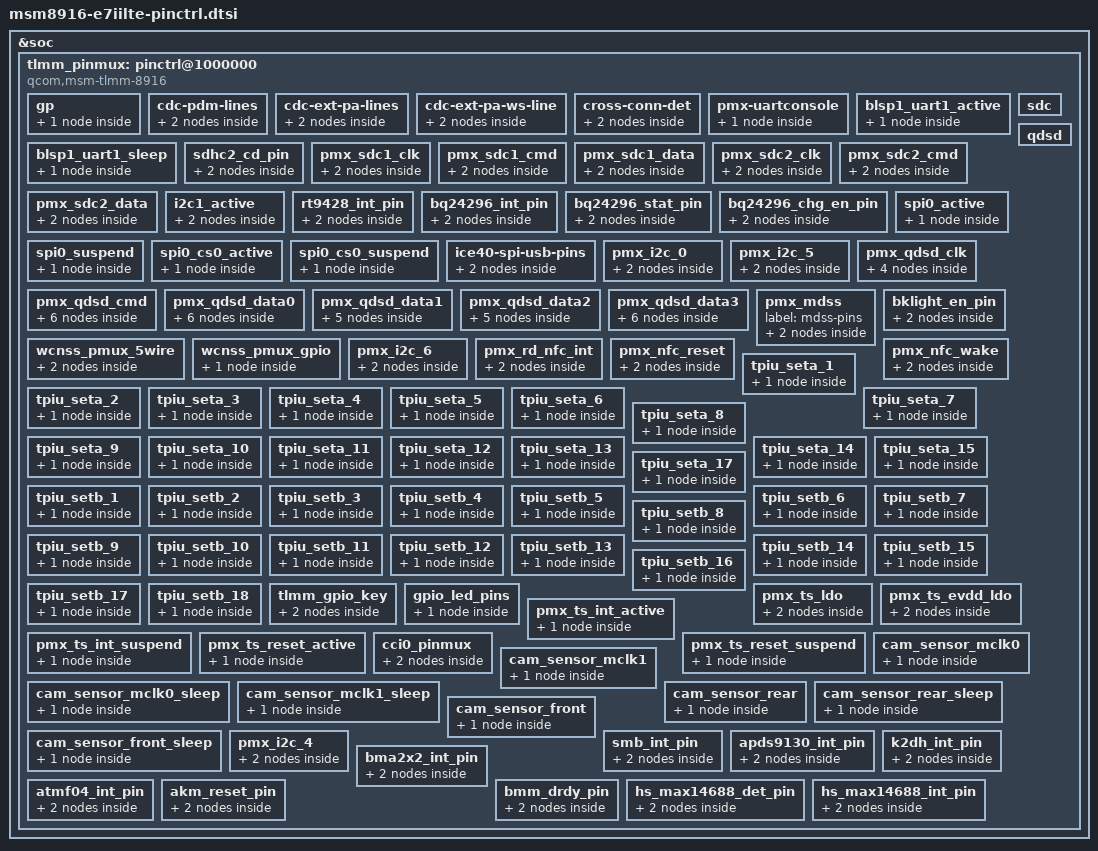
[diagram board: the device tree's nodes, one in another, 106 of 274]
/* Copyright (c) 2013-2014, The Linux Foundation. All rights reserved.
 *
 * This program is free software; you can redistribute it and/or modify
 * it under the terms of the GNU General Public License version 2 and
 * only version 2 as published by the Free Software Foundation.
 *
 * This program is distributed in the hope that it will be useful,
 * but WITHOUT ANY WARRANTY; without even the implied warranty of
 * MERCHANTABILITY or FITNESS FOR A PARTICULAR PURPOSE.  See the
 * GNU General Public License for more details.
 */

&soc {
	tlmm_pinmux: pinctrl@1000000 {
		compatible = "qcom,msm-tlmm-8916";
		reg = <0x1000000 0x300000>;
		interrupts = <0 208 0>;

		/*General purpose pins*/
		gp: gp {
			qcom,pin-type-gp;
			qcom,num-pins = <122>;
			#qcom,pin-cells = <1>;
			msm_gpio: msm_gpio {
				compatible = "qcom,msm-tlmm-gp";
				gpio-controller;
				#gpio-cells = <2>;
				interrupt-controller;
				#interrupt-cells = <2>;
				num_irqs = <122>;
			};
		};
		cdc-pdm-lines {
			qcom,pins = <&gp 63>, <&gp 64>, <&gp 65>,
					<&gp 66>, <&gp 67>, <&gp 68>;
			qcom,num-grp-pins = <6>;
			qcom,pin-func = <1>;
			label = "cdc-pdm-lines";
			cdc_pdm_lines_act: pdm_lines_on {
				drive-strength = <8>;
				bias-pull-none;
			};
			cdc_pdm_lines_sus: pdm_lines_off {
				drive-strength = <2>;
				bias-disable;
			};
		};

		cdc-ext-pa-lines {
			qcom,pins = <&gp 113>, <&gp 114>,
					<&gp 115>, <&gp 116>;
			qcom,num-grp-pins = <4>;
			qcom,pin-func = <1>;
			label = "cdc-ext-pa-lines";
			cdc_ext_pa_act: ext_pa_on {
				drive-strength = <8>;
				bias-pull-none;
			};
			cdc_ext_pa_sus: ext_pa_off {
				drive-strength = <2>;
				bias-disable;
			};
		};

		cdc-ext-pa-ws-line {
			qcom,pins = <&gp 110>;
			qcom,num-grp-pins = <1>;
			qcom,pin-func = <2>;
			label = "cdc-ext-pa-ws-line";
			cdc_ext_pa_ws_act: ext_pa_on {
				drive-strength = <8>;
				bias-pull-none;
			};
			cdc_ext_pa_ws_sus: ext_pa_off {
				drive-strength = <2>;
				bias-disable;
			};
		};

		cross-conn-det {
			qcom,pins = <&gp 120>;
			qcom,num-grp-pins = <1>;
			qcom,pin-func = <0>;
			label = "cross-conn-det-sw";
			cross_conn_det_act: lines_on {
				drive-strength = <8>;
				bias-pull-none;
			};
			cross_conn_det_sus: lines_off {
				drive-strength = <2>;
				bias-disable;
			};
		};
		pmx-uartconsole {
			qcom,pins = <&gp 4>, <&gp 5>;
			qcom,num-grp-pins = <2>;
			qcom,pin-func = <2>;
			label = "uart-console";

		uart_console_sleep: uart-console {
				drive-strength = <2>;
				bias-pull-down;
			};
		};

		blsp1_uart1_active {
			qcom,pins = <&gp 0>, <&gp 1>, <&gp 2>, <&gp 3>;
			qcom,num-grp-pins = <4>;
			qcom,pin-func = <2>;
		        label = "blsp1_uart1_active";

			hsuart_active: default {
				drive-strength = <16>;
				bias-disable;
			};
		};

		blsp1_uart1_sleep {
			qcom,pins = <&gp 0>, <&gp 1>, <&gp 2>, <&gp 3>;
			qcom,num-grp-pins = <4>;
			qcom,pin-func = <0>;
		        label = "blsp1_uart1_sleep";

			hsuart_sleep: sleep {
				drive-strength = <2>;
				bias-disable;
			};
		};

		sdhc2_cd_pin {
			qcom,pins = <&gp 38>;
			qcom,num-grp-pins = <1>;
			qcom,pin-func = <0>;
			label = "cd-gpio";
			sdc2_cd_on: cd_on {
				drive-strength = <2>;
				bias-pull-up;
			};
			sdc2_cd_off: cd_off {
				drive-strength = <2>;
				bias-disable;
			};
		};

		/* SDC pin type */
		sdc: sdc {
			qcom,pin-type-sdc;
			/* 0-2 for sdc1 4-6 for sdc2 */
			qcom,num-pins = <7>;
			/* Order of pins */
			/* SDC1: CLK -> 0, CMD -> 1, DATA -> 2 */
			/* SDC2: CLK -> 4, CMD -> 5, DATA -> 6 */
			#qcom,pin-cells = <1>;
		};

		pmx_sdc1_clk {
			qcom,pins = <&sdc 0>;
			qcom,num-grp-pins = <1>;
			label = "sdc1-clk";
			sdc1_clk_on: clk_on {
				bias-disable; /* NO pull */
				drive-strength = <14>; /* 14 MA */
			};
			sdc1_clk_off: clk_off {
				bias-disable; /* NO pull */
				drive-strength = <2>; /* 2 MA */
			};
		};

		pmx_sdc1_cmd {
			qcom,pins = <&sdc 1>;
			qcom,num-grp-pins = <1>;
			label = "sdc1-cmd";
			sdc1_cmd_on: cmd_on {
				bias-pull-up; /* pull up */
				drive-strength = <8>; /* 8 MA */
			};
			sdc1_cmd_off: cmd_off {
				bias-pull-up; /* pull up */
				drive-strength = <2>; /* 2 MA */
			};
		};

		pmx_sdc1_data {
			qcom,pins = <&sdc 2>;
			qcom,num-grp-pins = <1>;
			label = "sdc1-data";
			sdc1_data_on: data_on {
				bias-pull-up; /* pull up */
				drive-strength = <8>; /* 8 MA */
			};
			sdc1_data_off: data_off {
				bias-pull-up; /* pull up */
				drive-strength = <2>; /* 2 MA */
			};
		};

		pmx_sdc2_clk {
			qcom,pins = <&sdc 4>;
			qcom,num-grp-pins = <1>;
			label = "sdc2-clk";
			sdc2_clk_on: clk_on {
				bias-disable; /* NO pull */
				drive-strength = <16>; /* 16 MA */
			};
			sdc2_clk_off: clk_off {
				bias-disable; /* NO pull */
				drive-strength = <2>; /* 2 MA */
			};
		};

		pmx_sdc2_cmd {
			qcom,pins = <&sdc 5>;
			qcom,num-grp-pins = <1>;
			label = "sdc2-cmd";
			sdc2_cmd_on: cmd_on {
				bias-pull-up; /* pull up */
				drive-strength = <10>; /* 10 MA */
			};
			sdc2_cmd_off: cmd_off {
				bias-pull-up; /* pull up */
				drive-strength = <2>; /* 2 MA */
			};
		};

		pmx_sdc2_data {
			qcom,pins = <&sdc 6>;
			qcom,num-grp-pins = <1>;
			label = "sdc2-data";
			sdc2_data_on: data_on {
				bias-pull-up; /* pull up */
				drive-strength = <10>; /* 10 MA */
			};
			sdc2_data_off: data_off {
				bias-pull-up; /* pull up */
				drive-strength = <2>; /* 2 MA */
			};
		};

		/* BQ24296 Charger & RT9428 FuelGauge I2C */
		i2c1_active {
			/* CLK, DATA */
			qcom,pins = <&gp 2>, <&gp 3>;
			qcom,num-grp-pins = <2>;
			qcom,pin-func = <3>;
			label = "i2c1";
			/* active state */
			i2c_1_active: active {
				  drive-strength = <8>; /* 8 MA */
				  bias-disable = <0>; /* No PULL */
			  };
			i2c_1_sleep: sleep {
				 drive-strength = <8>; /* 8 MA */
				 bias-disable = <0>; /* No PULL */
			 };
		};

                /* RT9428 INT pin conifg */
		rt9428_int_pin {
			qcom,pins = <&gp 1>;
			qcom,num-grp-pins = <1>;
			qcom,pin-func = <0>;
			label = "rt9428_int_gpio";
			rt9428_int_active: rt9428_int_active {
				drive-strength = <6>;   /* 6 MA */
				bias-pull-up;           /* PULL UP*/
			};
			rt9428_int_sleep: rt9428_int_sleep {
				drive-strength = <6>;   /* 6 MA */
				bias-pull-up;           /* PULL UP */
			};

		};

		/* BQ24296 INT pin conifg */
		bq24296_int_pin {
			qcom,pins = <&gp 54>;
			qcom,num-grp-pins = <1>;
			qcom,pin-func = <0>;
			label = "bq24296_int_gpio";
			bq24296_int_active: bq24296_int_active {
				drive-strength = <6>;   /* 6 MA */
				bias-pull-up;           /* PULL UP*/
			};
			bq24296_int_sleep: bq24296_int_sleep {
				drive-strength = <6>;   /* 6 MA */
				bias-pull-up;           /* PULL UP */
			};
		};

		/* BQ24296 STAT pin config */
		bq24296_stat_pin {
			qcom,pins = <&gp 114>;
			qcom,num-grp-pins = <1>;
			qcom,pin-func = <0>;
			label = "bq24296_stat_gpio";
			bq24296_stat_active: bq24296_stat_active {
				drive-strength = <6>;   /* 6 MA */
				bias-pull-up;           /* PULL UP*/
			};
			bq24296_stat_sleep: bq24296_stat_sleep {
				drive-strength = <6>;   /* 6 MA */
				bias-pull-up;           /* PULL UP */
			};
		};

		/* BQ24296 CE pin config */
		bq24296_chg_en_pin {
			qcom,pins = <&gp 17>;
			qcom,num-grp-pins = <1>;
			qcom,pin-func = <0>;
			label = "bq24296_chg_en_gpio";
			bq24296_chg_en_active: bq24296_chg_en_active {
				drive-strength = <6>;   /* 6 MA */
				bias-pull-down = <0>;   /* PULL DOWN*/
			};
			bq24296_chg_en_sleep: bq24296_chg_en_sleep {
				drive-strength = <6>;   /* 6 MA */
				bias-pull-down = <0>;   /* PULL DOWN */
			};
		};

		spi0_active {
			/* MOSI, MISO, CLK */
			qcom,pins = <&gp 8>, <&gp 9>, <&gp 11>;
			qcom,num-grp-pins = <3>;
			qcom,pin-func = <1>;
			label = "spi0-active";
			/* active state */
			spi0_default: default {
				drive-strength = <12>; /* 12 MA */
				bias-disable = <0>; /* No PULL */
			};
		};

		spi0_suspend {
			/* MOSI, MISO, CLK */
			qcom,pins = <&gp 8>, <&gp 9>, <&gp 11>;
			qcom,num-grp-pins = <3>;
			qcom,pin-func = <0>;
			label = "spi0-suspend";
			/* suspended state */
			spi0_sleep: sleep {
				drive-strength = <2>; /* 2 MA */
				bias-pull-down; /* pull down */
			};
		};
		spi0_cs0_active {
			/* CS */
			qcom,pins = <&gp 10>;
			qcom,num-grp-pins = <1>;
			qcom,pin-func = <1>;
			label = "spi0-cs0-active";
			spi0_cs0_active: cs0_active {
				drive-strength = <2>;
				bias-disable = <0>;
			};
		};


		spi0_cs0_suspend {
			/* CS */
			qcom,pins = <&gp 10>;
			qcom,num-grp-pins = <1>;
			qcom,pin-func = <0>;
			label = "spi0-cs0-suspend";
			spi0_cs0_sleep: cs0_sleep {
				drive-strength = <2>;
				bias-disable = <0>;
			};
		};

		ice40-spi-usb-pins {
			qcom,pins = <&gp 0>, <&gp 1>, <&gp 3>, <&gp 114>;
			qcom,num-grp-pins = <4>;
			qcom,pin-func = <0>;
			label = "ice40-spi-usb-pins";

			/* active state */
			ice40_default: default {
				drive-strength = <8>;
				bias-disable;
			};

			/* sleep state */
			ice40_sleep: sleep {
				drive-strength = <2>;
				bias-pull-down;
			};
		};

		pmx_i2c_0 {
			/* CLK, DATA */
			qcom,pins = <&gp 7>, <&gp 6>;
			qcom,num-grp-pins = <2>;
			qcom,pin-func = <3>;
			label = "pmx_i2c_0";

			i2c_0_active: i2c_0_active {
				drive-strength = <2>; /* 2 MA */
				bias-disable;         /* No PULL */
			};

			i2c_0_sleep: i2c_0_sleep {
				drive-strength = <2>; /* 2 MA */
				bias-disable;	      /* No PULL */
			};
		};

		pmx_i2c_5 {
			/* CLK, DATA */
			qcom,pins = <&gp 19>, <&gp 18>;
			qcom,num-grp-pins = <2>;
			qcom,pin-func = <2>;
			label = "pmx_i2c_5";

			i2c_5_active: i2c_5_active {
				drive-strength = <2>; /* 2 MA */
				bias-disable = <0>; /* No PULL */
			};

			i2c_5_sleep: i2c_5_sleep {
				drive-strength = <2>; /* 2 MA */
				bias-disable = <0>; /* No PULL */
			};
		};

		/* QDSD pin type */
		qdsd: qdsd {
			qcom,pin-type-qdsd;
			/* 0-> clk, 1 -> cmd, 2->data0, 3->data1, 4->data2, 5->data3 */
			qcom,num-pins = <6>;

			#qcom,pin-cells = <1>;
		};

		pmx_qdsd_clk {
			qcom,pins = <&qdsd 0>;
			qcom,num-grp-pins = <1>;
			label = "qdsd-clk";
			qdsd_clk_sdcard: clk_sdcard {
				bias-disable; /* NO pull */
				drive-strength = <7>; /* 7 MA */
			};
			qdsd_clk_trace: clk_trace {
				bias-pull-down; /* pull down */
				drive-strength = <0>; /* 0 MA */
			};
			qdsd_clk_swdtrc: clk_swdtrc {
				bias-pull-down; /* pull down */
				drive-strength = <0>; /* 0 MA */
			};
			qdsd_clk_spmi: clk_spmi {
				bias-pull-down; /* pull down */
				drive-strength = <0>; /* 0 MA */
			};
		};

		pmx_qdsd_cmd {
			qcom,pins = <&qdsd 1>;
			qcom,num-grp-pins = <1>;
			label = "qdsd-cmd";
			qdsd_cmd_sdcard: cmd_sdcard {
				bias-pull-down; /* pull down */
				drive-strength = <3>; /* 3 MA */
			};
			qdsd_cmd_trace: cmd_trace {
				bias-pull-down; /* pull down */
				drive-strength = <0>; /* 0 MA */
			};
			qdsd_cmd_swduart: cmd_uart {
				bias-pull-up; /* pull up */
				drive-strength = <0>; /* 0 MA */
			};
			qdsd_cmd_swdtrc: cmd_swdtrc {
				bias-pull-up; /* pull up */
				drive-strength = <0>; /* 0 MA */
			};
			qdsd_cmd_jtag: cmd_jtag {
				bias-disable; /* NO pull */
				drive-strength = <3>; /* 3 MA */
			};
			qdsd_cmd_spmi: cmd_spmi {
				bias-pull-down; /* pull down */
				drive-strength = <4>; /* 4 MA */
			};
		};

		pmx_qdsd_data0 {
			qcom,pins = <&qdsd 2>;
			qcom,num-grp-pins = <1>;
			label = "qdsd-data0";
			qdsd_data0_sdcard: data0_sdcard {
				bias-pull-down; /* pull down */
				drive-strength = <3>; /* 3 MA */
			};
			qdsd_data0_trace: data0_trace {
				bias-pull-down; /* pull down */
				drive-strength = <0>; /* 0 MA */
			};
			qdsd_data0_swduart: data0_uart {
				bias-pull-down; /* pull down */
				drive-strength = <0>; /* 0 MA */
			};
			qdsd_data0_swdtrc: data0_swdtrc {
				bias-pull-down; /* pull down */
				drive-strength = <0>; /* 0 MA */
			};
			qdsd_data0_jtag: data0_jtag {
				bias-pull-up; /* pull up */
				drive-strength = <0>; /* 0 MA */
			};
			qdsd_data0_spmi: data0_spmi {
				bias-pull-down; /* pull down */
				drive-strength = <0>; /* 0 MA */
			};
		};

		pmx_qdsd_data1 {
			qcom,pins = <&qdsd 3>;
			qcom,num-grp-pins = <1>;
			label = "qdsd-data1";
			qdsd_data1_sdcard: data1_sdcard {
				bias-pull-down; /* pull down */
				drive-strength = <3>; /* 3 MA */
			};
			qdsd_data1_trace: data1_trace {
				bias-pull-down; /* pull down */
				drive-strength = <0>; /* 0 MA */
			};
			qdsd_data1_swduart: data1_uart {
				bias-pull-down; /* pull down */
				drive-strength = <0>; /* 0 MA */
			};
			qdsd_data1_swdtrc: data1_swdtrc {
				bias-pull-down; /* pull down */
				drive-strength = <0>; /* 0 MA */
			};
			qdsd_data1_jtag: data1_jtag {
				bias-pull-down; /* pull down */
				drive-strength = <0>; /* 0 MA */
			};
		};

		pmx_qdsd_data2 {
			qcom,pins = <&qdsd 4>;
			qcom,num-grp-pins = <1>;
			label = "qdsd-data2";
			qdsd_data2_sdcard: data2_sdcard {
				bias-pull-down; /* pull down */
				drive-strength = <3>; /* 3 MA */
			};
			qdsd_data2_trace: data2_trace {
				bias-pull-down; /* pull down */
				drive-strength = <0>; /* 0 MA */
			};
			qdsd_data2_swduart: data2_uart {
				bias-pull-down; /* pull down */
				drive-strength = <0>; /* 0 MA */
			};
			qdsd_data2_swdtrc: data2_swdtrc {
				bias-pull-down; /* pull down */
				drive-strength = <0>; /* 0 MA */
			};
			qdsd_data2_jtag: data2_jtag {
				bias-pull-up; /* pull up */
				drive-strength = <3>; /* 3 MA */
			};
		};

		pmx_qdsd_data3 {
			qcom,pins = <&qdsd 5>;
			qcom,num-grp-pins = <1>;
			label = "qdsd-data3";
			qdsd_data3_sdcard: data3_sdcard {
				bias-pull-down; /* pull down */
				drive-strength = <3>; /* 3 MA */
			};
			qdsd_data3_trace: data3_trace {
				bias-pull-down; /* pull down */
				drive-strength = <0>; /* 0 MA */
			};
			qdsd_data3_swduart: data3_uart {
				bias-pull-up; /* pull up */
				drive-strength = <0>; /* 0 MA */
			};
			qdsd_data3_swdtrc: data3_swdtrc {
				bias-pull-up; /* pull up */
				drive-strength = <0>; /* 0 MA */
			};
			qdsd_data3_jtag: data3_jtag {
				bias-pull-up; /* pull up */
				drive-strength = <0>; /* 0 MA */
			};
			qdsd_data3_spmi: data3_spmi {
				bias-pull-down; /* pull down */
				drive-strength = <3>; /* 3 MA */
			};
		};

		pmx_mdss: pmx_mdss {
			label = "mdss-pins";
			mdss_dsi_active: active {
				drive-strength = <8>; /* 8 mA */
				bias-disable = <0>; /* no pull */
			};
			mdss_dsi_suspend: suspend {
				drive-strength = <2>; /* 2 mA */
				bias-disable = <0>; /* pull down */
			};
		};

		/* backlight enable pin config */
		bklight_en_pin {
			qcom,pins = <&gp 98>;
			qcom,num-grp-pins = <1>;
			qcom,pin-func = <0>;
			label = "bklight_en_pin";
			bklight_en_active: bklight_en_active {
				drive-strength = <6>;   /* 6 MA */
				bias-disable; 		/* NO PULL */
			};
			bklight_en_suspend: bklight_en_suspend {
				drive-strength = <6>;   /* 6 MA */
				bias-disable; 		/* NO PULL */
			};
		};

		wcnss_pmux_5wire: wcnss_pmux_5wire {
			/* Uses general purpose pins */
			qcom,pins = <&gp 40>, <&gp 41>,
				    <&gp 42>, <&gp 43>,
				    <&gp 44>;
			qcom,num-grp-pins = <5>;
			qcom,pin-func = <1>;
			label = "wcnss_5wire_pins";
			/* Active configuration of bus pins */
			wcnss_default: wcnss_default {
			        drive-strength = <6>; /* 6 MA */
			        bias-pull-up; /* PULL UP */
			};
			wcnss_sleep: wcnss_sleep {
			        drive-strength = <2>; /* 2 MA */
			        bias-pull-down; /* PULL Down */
			};
		};

		wcnss_pmux_gpio: wcnss_pmux_gpio {
			/* Uses general purpose pins */
			qcom,pins = <&gp 40>, <&gp 41>,
				    <&gp 42>, <&gp 43>,
				    <&gp 44>;
			qcom,num-grp-pins = <5>;
			qcom,pin-func = <0>;
			label = "wcnss_5gpio_pins";
			/* Active configuration of bus pins */
			wcnss_gpio_default: wcnss_gpio_default {
			        drive-strength = <6>; /* 6 MA */
			        bias-pull-up; /* PULL UP */
			};
		};

		pmx_i2c_6 {
			/* CLK, DATA */
			qcom,pins = <&gp 22>, <&gp 23>;
			qcom,num-grp-pins = <2>;
			qcom,pin-func = <2>;
			label = "pmx_i2c_6";
			/* active state */
			i2c_6_active: i2c_6_active{
				drive-strength = <2>; /* 2 MA */
				bias-disable; /* No PULL */
			};
			/*suspended state */
			i2c_6_sleep: i2c_6_sleep {
				drive-strength = <2>; /* 2 MA */
				bias-disable; /* No PULL */
			};
		};

		pmx_rd_nfc_int{
			qcom,pins = <&gp 21>;
			qcom,pin-func = <0>;
			qcom,num-grp-pins = <1>;
			label = "pmx_nfc_int";

			nfc_int_active: active {
				drive-strength = <6>;
				bias-pull-up;
			};

			nfc_int_suspend: suspend {
				drive-strength = <6>;
				bias-pull-up;
			};
		};

		pmx_nfc_reset{
			qcom,pins = <&gp 20>;
			qcom,pin-func = <0>;
			qcom,num-grp-pins = <1>;
			label = "pmx_nfc_disable";

			nfc_disable_active: active {
				drive-strength = <6>;
				bias-pull-up;
			};

			nfc_disable_suspend: suspend {
				drive-strength = <6>;
				bias-disable;
			};
		};

		pmx_nfc_wake{
			qcom,pins = <&gp 118>;
			qcom,pin-func = <0>;
			qcom,num-grp-pins = <1>;
			label = "pmx_nfc_wake";

			nfc_wake_active: active {
				drive-strength = <6>;
				bias-pull-up;
			};
			nfc_wake_suspend: suspend {
				drive-strength = <6>;
				bias-disable;
			};
		};

		/* CoreSight */
		tpiu_seta_1 {
			qcom,pins = <&gp 8>;
			qcom,num-grp-pins = <1>;
			qcom,pin-func = <3>;
			label = "tpiu-seta-1";
			seta_1: seta {
				drive-strength = <16>;
				bias-disable;
			};
		};

		tpiu_seta_2 {
			qcom,pins = <&gp 9>;
			qcom,num-grp-pins = <1>;
			qcom,pin-func = <2>;
			label = "tpiu-seta-2";
			seta_2: seta {
				drive-strength = <16>;
				bias-disable;
			};
		};

		tpiu_seta_3 {
			qcom,pins = <&gp 10>;
			qcom,num-grp-pins = <1>;
			qcom,pin-func = <3>;
			label = "tpiu-seta-3";
			seta_3: seta {
				drive-strength = <16>;
				bias-disable;
			};
		};

		tpiu_seta_4 {
			qcom,pins = <&gp 39>;
			qcom,num-grp-pins = <1>;
			qcom,pin-func = <2>;
			label = "tpiu-seta-4";
			seta_4: seta {
				drive-strength = <16>;
				bias-disable;
			};
		};

		tpiu_seta_5 {
			qcom,pins = <&gp 40>;
			qcom,num-grp-pins = <1>;
			qcom,pin-func = <2>;
			label = "tpiu-seta-5";
			seta_5: seta {
				drive-strength = <16>;
				bias-disable;
			};
		};

		tpiu_seta_6 {
			qcom,pins = <&gp 41>;
			qcom,num-grp-pins = <1>;
			qcom,pin-func = <2>;
			label = "tpiu-seta-6";
			seta_6: seta {
				drive-strength = <16>;
				bias-disable;
			};
		};

		tpiu_seta_7 {
			qcom,pins = <&gp 42>;
			qcom,num-grp-pins = <1>;
			qcom,pin-func = <2>;
			label = "tpiu-seta-7";
			seta_7: seta {
				drive-strength = <16>;
				bias-disable;
			};
		};

		tpiu_seta_8 {
			qcom,pins = <&gp 43>;
			qcom,num-grp-pins = <1>;
			qcom,pin-func = <3>;
			label = "tpiu-seta-8";
			seta_8: seta {
				drive-strength = <16>;
				bias-disable;
			};
		};

		tpiu_seta_9 {
			qcom,pins = <&gp 45>;
			qcom,num-grp-pins = <1>;
			qcom,pin-func = <3>;
			label = "tpiu-seta-9";
			seta_9: seta {
				drive-strength = <16>;
				bias-disable;
			};
		};

		tpiu_seta_10 {
			qcom,pins = <&gp 46>;
			qcom,num-grp-pins = <1>;
			qcom,pin-func = <2>;
			label = "tpiu-seta-10";
			seta_10: seta {
				drive-strength = <16>;
				bias-disable;
			};
		};

		tpiu_seta_11 {
			qcom,pins = <&gp 47>;
			qcom,num-grp-pins = <1>;
			qcom,pin-func = <3>;
			label = "tpiu-seta-11";
			seta_11: seta {
				drive-strength = <16>;
				bias-disable;
			};
		};

		tpiu_seta_12 {
			qcom,pins = <&gp 48>;
			qcom,num-grp-pins = <1>;
			qcom,pin-func = <2>;
			label = "tpiu-seta-12";
			seta_12: seta {
				drive-strength = <16>;
				bias-disable;
			};
		};

		tpiu_seta_13 {
			qcom,pins = <&gp 62>;
			qcom,num-grp-pins = <1>;
			qcom,pin-func = <2>;
			label = "tpiu-seta-13";
			seta_13: seta {
				drive-strength = <16>;
				bias-disable;
			};
		};

		tpiu_seta_14 {
			qcom,pins = <&gp 69>;
			qcom,num-grp-pins = <1>;
			qcom,pin-func = <2>;
			label = "tpiu-seta-14";
			seta_14: seta {
				drive-strength = <16>;
				bias-disable;
			};
		};

		tpiu_seta_15 {
			qcom,pins = <&gp 112>;
			qcom,num-grp-pins = <1>;
			qcom,pin-func = <5>;
			label = "tpiu-seta-15";
			seta_15: seta {
				drive-strength = <16>;
				bias-disable;
			};
		};

		tpiu_seta_17 {
			qcom,pins = <&gp 114>;
			qcom,num-grp-pins = <1>;
			qcom,pin-func = <8>;
			label = "tpiu-seta-17";
			seta_17: seta {
				drive-strength = <16>;
				bias-disable;
			};
		};

		tpiu_setb_1 {
			qcom,pins = <&gp 4>;
			qcom,num-grp-pins = <1>;
			qcom,pin-func = <5>;
			label = "tpiu-setb-1";
			setb_1: setb {
				drive-strength = <16>;
				bias-disable;
			};
		};

		tpiu_setb_2 {
			qcom,pins = <&gp 5>;
			qcom,num-grp-pins = <1>;
			qcom,pin-func = <5>;
			label = "tpiu-setb-2";
			setb_2: setb {
				drive-strength = <16>;
				bias-disable;
			};
		};

		tpiu_setb_3 {
			qcom,pins = <&gp 26>;
			qcom,num-grp-pins = <1>;
			qcom,pin-func = <7>;
			label = "tpiu-setb-3";
			setb_3: setb {
				drive-strength = <16>;
				bias-disable;
			};
		};

		tpiu_setb_4 {
			qcom,pins = <&gp 27>;
			qcom,num-grp-pins = <1>;
			qcom,pin-func = <9>;
			label = "tpiu-setb-4";
			setb_4: setb {
				drive-strength = <16>;
				bias-disable;
			};
		};

		tpiu_setb_5 {
			qcom,pins = <&gp 28>;
			qcom,num-grp-pins = <1>;
			qcom,pin-func = <7>;
			label = "tpiu-setb-5";
			setb_5: setb {
				drive-strength = <16>;
				bias-disable;
			};
		};

		tpiu_setb_6 {
			qcom,pins = <&gp 29>;
			qcom,num-grp-pins = <1>;
			qcom,pin-func = <7>;
			label = "tpiu-setb-6";
			setb_6: setb {
				drive-strength = <16>;
				bias-disable;
			};
		};

		tpiu_setb_7 {
			qcom,pins = <&gp 30>;
			qcom,num-grp-pins = <1>;
			qcom,pin-func = <9>;
			label = "tpiu-setb-7";
			setb_7: setb {
				drive-strength = <16>;
				bias-disable;
			};
		};

		tpiu_setb_8 {
			qcom,pins = <&gp 31>;
			qcom,num-grp-pins = <1>;
			qcom,pin-func = <10>;
			label = "tpiu-setb-8";
			setb_8: setb {
				drive-strength = <16>;
				bias-disable;
			};
		};

		tpiu_setb_9 {
			qcom,pins = <&gp 32>;
			qcom,num-grp-pins = <1>;
			qcom,pin-func = <10>;
			label = "tpiu-setb-9";
			setb_9: setb {
				drive-strength = <16>;
				bias-disable;
			};
		};

		tpiu_setb_10 {
			qcom,pins = <&gp 33>;
			qcom,num-grp-pins = <1>;
			qcom,pin-func = <9>;
			label = "tpiu-setb-10";
			setb_10: setb {
				drive-strength = <16>;
				bias-disable;
			};
		};

		tpiu_setb_11 {
			qcom,pins = <&gp 34>;
			qcom,num-grp-pins = <1>;
			qcom,pin-func = <9>;
			label = "tpiu-setb-11";
			setb_11: setb {
				drive-strength = <16>;
				bias-disable;
			};
		};

		tpiu_setb_12 {
			qcom,pins = <&gp 35>;
			qcom,num-grp-pins = <1>;
			qcom,pin-func = <9>;
			label = "tpiu-setb-12";
			setb_12: setb {
				drive-strength = <16>;
				bias-disable;
			};
		};

		tpiu_setb_13 {
			qcom,pins = <&gp 36>;
			qcom,num-grp-pins = <1>;
			qcom,pin-func = <8>;
			label = "tpiu-setb-13";
			setb_13: setb {
				drive-strength = <16>;
				bias-disable;
			};
		};

		tpiu_setb_14 {
			qcom,pins = <&gp 37>;
			qcom,num-grp-pins = <1>;
			qcom,pin-func = <7>;
			label = "tpiu-setb-14";
			setb_14: setb {
				drive-strength = <16>;
				bias-disable;
			};
		};

		tpiu_setb_15 {
			qcom,pins = <&gp 110>;
			qcom,num-grp-pins = <1>;
			qcom,pin-func = <4>;
			label = "tpiu-setb-15";
			setb_15: setb {
				drive-strength = <16>;
				bias-disable;
			};
		};

		tpiu_setb_16 {
			qcom,pins = <&gp 111>;
			qcom,num-grp-pins = <1>;
			qcom,pin-func = <1>;
			label = "tpiu-setb-16";
			setb_16: setb {
				drive-strength = <16>;
				bias-disable;
			};
		};

		tpiu_setb_17 {
			qcom,pins = <&gp 120>;
			qcom,num-grp-pins = <1>;
			qcom,pin-func = <10>;
			label = "tpiu-setb-17";
			setb_17: setb {
				drive-strength = <16>;
				bias-disable;
			};
		};

		tpiu_setb_18 {
			qcom,pins = <&gp 121>;
			qcom,num-grp-pins = <1>;
			qcom,pin-func = <11>;
			label = "tpiu-setb-18";
			setb_18: setb {
				drive-strength = <16>;
				bias-disable;
			};
		};

		tlmm_gpio_key {
			qcom,pins = <&gp 107>, <&gp 108>;
			qcom,pin-func = <0>;
			qcom,num-grp-pins = <2>;
			label = "tlmm_gpio_key";
			gpio_key_active: gpio_key_active {
				drive-strength = <2>;
				bias-pull-up;
			};
			gpio_key_suspend: gpio_key_suspend {
				drive-strength = <2>;
				bias-pull-up;
			};
		};

		gpio_led_pins {
			qcom,pins = <&gp 8>, <&gp 9>, <&gp 10>;
			qcom,num-grp-pins = <3>;
			label = "gpio-led-pins";
			gpio_led_off: led_off {
				drive-strength = <2>;
				bias-disable;
				output-low;
			};
		};

		/* add pingrp for touchscreen */
		pmx_ts_ldo {
			qcom,pins = <&gp 32>, <&gp 34>, <&gp 36>;
			qcom,pin-func = <0>;
			qcom,num-grp-pins = <3>;
			label = "pmx_ts_ldo_active";

			ts_ldo_active: ts_ldo_active {
				drive-strength = <2>;
				output-high;
			};

			ts_ldo_suspend: ts_ldo_suspend {
				drive-strength = <2>;
				output-low;
			};
		};

		pmx_ts_evdd_ldo {
			qcom,pins = <&gp 9>;
			qcom,pin-func = <0>;
			qcom,num-grp-pins = <1>;
			label = "pmx_ts_evdd_ldo_active";

			ts_evdd_ldo_active: ts_evdd_ldo_active {
				drive-strength = <2>;
				output-high;
			};

			ts_evdd_ldo_suspend: ts_evdd_ldo_suspend {
				drive-strength = <2>;
				output-low;
			};
		};


		/* add pingrp for touchscreen */
		pmx_ts_int_active {
			qcom,pins = <&gp 13>;
			qcom,pin-func = <0>;
			qcom,num-grp-pins = <1>;
			label = "pmx_ts_int_active";

			ts_int_active: ts_int_active {
				drive-strength = <16>;
				bias-pull-up;
			};
		};

		pmx_ts_int_suspend {
			qcom,pins = <&gp 13>;
			qcom,pin-func = <0>;
			qcom,num-grp-pins = <1>;
			label = "pmx_ts_int_suspend";

			ts_int_suspend: ts_int_suspend {
				drive-strength = <2>;
				bias-pull-down;
			};
		};

		pmx_ts_reset_active {
			qcom,pins = <&gp 12>;
			qcom,pin-func = <0>;
			qcom,num-grp-pins = <1>;
			label = "pmx_ts_reset_active";

			ts_reset_active: ts_reset_active {
				drive-strength = <16>;
				bias-pull-up;
			};
		};

		pmx_ts_reset_suspend {
			qcom,pins = <&gp 12>;
			qcom,pin-func = <0>;
			qcom,num-grp-pins = <1>;
			label = "pmx_ts_reset_suspend";

			ts_reset_suspend: ts_reset_suspend {
				drive-strength = <2>;
				bias-pull-down;
			};
		};

		/*
		pmx_ts_reset {
			qcom,pins = <&gp 12>;
			qcom,pin-func = <0>;
			qcom,num-grp-pins = <1>;
			label = "pmx_ts_reset_active";

			ts_reset_active: ts_reset_active {
				drive-strength = <2>;
				output-high;
			};

			ts_reset_suspend: ts_reset_suspend {
				drive-strength = <2>;
				output-low;
			};
		};

		pmx_ts_int {
			qcom,pins = <&gp 13>;
			qcom,pin-func = <0>;
			qcom,num-grp-pins = <1>;
			label = "pmx_ts_int_active";

			ts_int_active: ts_int_active {
				drive-strength = <2>;
				bias-pull-up;
			};

			ts_int_suspend: ts_int_suspend {
				drive-strength = <2>;
				bias-pull-down;
			};
		};
		*/

		cci0_pinmux {
			/* CLK, DATA */
			qcom,pins = <&gp 29>, <&gp 30>;
			qcom,num-grp-pins = <2>;
			qcom,pin-func = <1>;
			label = "cci0";
			/* active state */
			cci0_default: default {
				drive-strength = <2>; /* 2 MA */
				bias-disable = <0>; /* No PULL */
			};
			/*suspended state */
			cci0_sleep: sleep {
				drive-strength = <2>; /* 2 MA */
				bias-disable = <0>; /* No PULL */
			};
		};

		cam_sensor_mclk0 {
			/* MCLK */
			qcom,pins = <&gp 26>;
			qcom,num-grp-pins = <1>;
			qcom,pin-func = <1>;
			label = "cam-sensor-mclk0";
			/* active state */
			cam_sensor_mclk0_default: default {
				drive-strength = <2>; /* 2 MA */
				bias-disable = <0>; /* No PULL */
			};
		};

		cam_sensor_mclk0_sleep {
			/* MCLK */
			qcom,pins = <&gp 26>;
			qcom,num-grp-pins = <1>;
			label = "cam-sensor-mclk0-sleep";
			/* suspend state */
			cam_sensor_mclk0_sleep: sleep {
				drive-strength = <2>; /* 2 MA */
				bias-pull-down; /* PULL DOWN */
			};
		};

		cam_sensor_mclk1 {
			/* MCLK */
			qcom,pins = <&gp 27>;
			qcom,num-grp-pins = <1>;
			qcom,pin-func = <1>;
			label = "cam-sensor-mclk1";
			/* active state */
			cam_sensor_mclk1_default: default {
				drive-strength = <2>; /* 2 MA */
				bias-disable = <0>; /* No PULL */
			};
		};

		cam_sensor_mclk1_sleep {
			/* MCLK */
			qcom,pins = <&gp 27>;
			qcom,num-grp-pins = <1>;
			label = "cam-sensor-mclk1-sleep";
			/* suspend state */
			cam_sensor_mclk1_sleep: sleep {
				drive-strength = <2>; /* 2 MA */
				bias-pull-down; /* PULL DOWN */
			};
		};

		cam_sensor_rear {
			/* RESET, STANDBY */
			//qcom,pins =  <&gp 35>, <&gp 34>;

			/* RESET */
			qcom,pins =  <&gp 35>;
			qcom,num-grp-pins = <1>; //<2>
			qcom,pin-func = <0>;
			label = "cam-sensor-rear";
			/* active state */
			cam_sensor_rear_default: default {
				drive-strength = <2>; /* 2 MA */
				bias-disable = <0>; /* No PULL */
			};
		};

		cam_sensor_rear_sleep {
			/* RESET, STANDBY */
			//qcom,pins =  <&gp 35>, <&gp 34>;

			/* RESET */
			qcom,pins =  <&gp 35>;
			qcom,num-grp-pins = <1>; //<2>
			qcom,pin-func = <0>;
			label = "cam-sensor-rear-sleep";
			/*suspended state */
			cam_sensor_rear_sleep: sleep {
				drive-strength = <2>; /* 2 MA */
				bias-pull-down; /* PULL DOWN */
			};
		};

		cam_sensor_front {
			/* RESET, STANDBY */
			qcom,pins = <&gp 28>, <&gp 33>;
			qcom,num-grp-pins = <2>;
			qcom,pin-func = <0>;
			label = "cam_sensor_front";
			/* active state */
			cam_sensor_front_default: default {
				drive-strength = <2>; /* 2 MA */
				bias-disable = <0>; /* No PULL */
			};
		};

		cam_sensor_front_sleep {
			/* RESET, STANDBY */
			qcom,pins = <&gp 28>, <&gp 33>;
			qcom,num-grp-pins = <2>;
			qcom,pin-func = <0>;
			label = "cam_sensor_front";
			/*suspended state */
			cam_sensor_front_sleep: sleep {
				drive-strength = <2>; /* 2 MA */
				bias-pull-down = <0>; /* PULL DOWN */
			};
		};


		pmx_i2c_4 {
			/* CLK, DATA */
			qcom,pins = <&gp 14>, <&gp 15>;
			qcom,num-grp-pins = <2>;
			qcom,pin-func = <2>;
			label = "pmx_i2c_4";

			i2c_4_active: i2c_4_active {
				drive-strength = <2>;	/* 2 MA */
				bias-disable = <0>;	/* No PULL */
			};

			i2c_4_sleep: i2c_4_sleep {
				drive-strength = <2>;	/* 2 MA */
				bias-disable = <0>;	/* No PULL */
			};

		};

		smb_int_pin {
			qcom,pins = <&gp 62>;
			qcom,num-grp-pins = <1>;
			qcom,pin-func = <0>;
			label = "smb1360_int_gpio";
			smb_int_active: smb_int_active {
				drive-strength = <2>;	/* 2 MA */
				bias-pull-up;		/* PULL UP*/
			};
			smb_int_sleep: smb_int_sleep {
				drive-strength = <2>;	/* 2 MA */
				bias-pull-up;		/* PULL UP */
			};
		};


		/* apds9130 irq pin config */
		apds9130_int_pin {
			qcom,pins = <&gp 113>;
			qcom,num-grp-pins = <1>;
			qcom,pin-func = <0>;
			label = "apds9130_int_pin";
			apds9130_int_active: apds9130_int_active {
				drive-strength = <6>;   /* 6 MA */
				bias-pull-up;           /* PULL UP*/
			};
			apds9130_int_suspend: apds9130_int_suspend {
				drive-strength = <6>;   /* 6 MA */
				bias-disable; 		/* NO PULL */
			};
		};

		/* K2DH irq pin config */
		k2dh_int_pin {
			qcom,pins = <&gp 115>;
			qcom,num-grp-pins = <1>;
			qcom,pin-func = <0>;
			label = "k2dh_int_pin";
			k2dh_int_active: k2dh_int_active {
				drive-strength = <6>;   /* 6 MA */
				bias-pull-up;           /* PULL UP*/
			};
			k2dh_int_suspend: k2dh_int_suspend {
				drive-strength = <6>;   /* 6 MA */
				bias-disable; 		/* NO PULL */
			};
		};

		/* bma2x2 irq pin config */
		bma2x2_int_pin {
			qcom,pins = <&gp 115>;
			qcom,num-grp-pins = <1>;
			qcom,pin-func = <0>;
			label = "bma2x2_int_pin";
			bma2x2_int_active: bma2x2_int_active {
				drive-strength = <6>;   /* 6 MA */
				bias-pull-up;           /* PULL UP*/
			};
			bma2x2_int_suspend: bma2x2_int_suspend {
				drive-strength = <6>;   /* 6 MA */
				bias-disable; 		/* NO PULL */
			};
		};


         /* atmf04 irq pin config */
         atmf04_int_pin {
             qcom,pins = <&gp 112>;
             qcom,num-grp-pins = <1>;
             qcom,pin-func = <0>;
             label = "atmf04_int_pin";
             atmf04_int_active: atmf04_int_active {
                 drive-strength = <2>;   /* 6 MA */
                 bias-pull-up;           /* PULL UP*/
             };
             atmf04_int_suspend: atmf04_int_suspend {
                 drive-strength = <2>;   /* 6 MA */
                 bias-disable;           /* NO PULL */
             };
         };


		/* akm09911 reset pin config */
		akm_reset_pin {
	                qcom,pins = <&gp 69>;
	                qcom,pin-func = <0>;
	                qcom,num-grp-pins = <1>;
	                label = "akm_reset_pin";
	                akm09911_active: akm09911_active {
	                          drive-strength = <6>;
	                          bias-pull-up;
	                };
	                akm09911_suspend: akm0991_suspend {
	                           drive-strength = <6>;
	                           bias-pull-down;
	                };
	        };

		/* bmm drdy pin config */
		bmm_drdy_pin {
	                qcom,pins = <&gp 69>;
	                qcom,pin-func = <0>;
	                qcom,num-grp-pins = <1>;
	                label = "bmm_drdy_pin";
	                bmm_drdy_active: bmm_drdy_active {
	                          drive-strength = <6>;
	                          bias-pull-up;
	                };
	                bmm_drdy_suspend: bmm_drdy_suspend {
	                           drive-strength = <6>;
	                           bias-pull-down;
	                };
	        };

		/* MAX14688 Headset Detection IC */
		hs_max14688_det_pin {
			qcom,pins = <&gp 110>;
			qcom,num-grp-pins = <1>;
			qcom,pin-func = <0>;
			label = "hs_max14688_det_pin";
			hs_max14688_det_active: hs_max14688_det_active {
				drive-strength = <6>;   /* 6 MA */
				bias-pull-up;           /* PULL UP*/
			};
			hs_max14688_det_sleep: hs_max14688_det_sleep {
				drive-strength = <6>;   /* 6 MA */
				bias-disable;
			};
		};

		hs_max14688_int_pin {
			qcom,pins = <&gp 114>;
			qcom,num-grp-pins = <1>;
			qcom,pin-func = <0>;
			label = "hs_max14688_int_pin";
			hs_max14688_int_active: hs_max14688_int_active {
				drive-strength = <6>;   /* 6 MA */
				bias-pull-up;           /* PULL UP*/
			};
			hs_max14688_int_sleep: hs_max14688_int_sleep {
				drive-strength = <6>;   /* 6 MA */
				bias-disable;
			};
		};

	};
};
